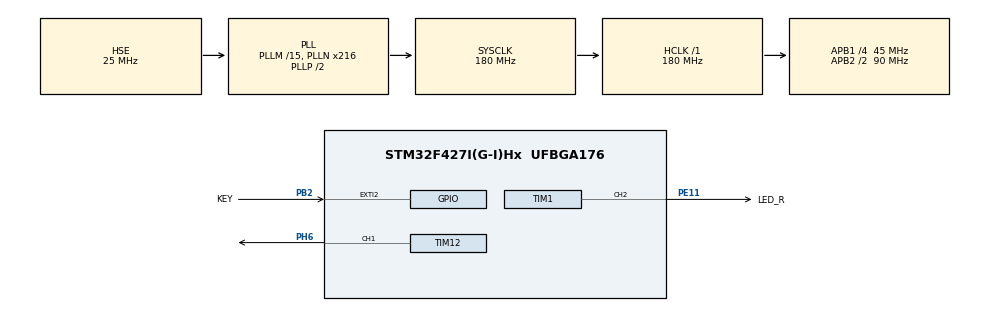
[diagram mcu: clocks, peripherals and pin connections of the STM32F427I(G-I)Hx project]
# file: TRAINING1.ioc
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IWDG.Prescaler=IWDG_PRESCALER_16
IWDG.Reload=3999
Mcu.Family=STM32F4
Mcu.Name=STM32F427I(G-I)Hx
Mcu.Package=UFBGA176
NVIC.EXTI2_IRQn=true\:0\:0\:true\:false\:true\:true\:true\:true
NVIC.PriorityGroup=NVIC_PRIORITYGROUP_4
PA13.Mode=Serial_Wire
PA13.Signal=SYS_JTMS-SWDIO
PA14.Mode=Serial_Wire
PA14.Signal=SYS_JTCK-SWCLK
PB2/BOOT1.GPIO_Label=KEY
PB2/BOOT1.GPIO_ModeDefaultEXTI=GPIO_MODE_IT_RISING
PB2/BOOT1.GPIO_PuPd=GPIO_PULLDOWN
PB2/BOOT1.Signal=GPXTI2
PE11.GPIO_Label=LED_R
PE11.Signal=S_TIM1_CH2
PH0/OSC_IN.Mode=HSE-External-Oscillator
PH0/OSC_IN.Signal=RCC_OSC_IN
PH1/OSC_OUT.Mode=HSE-External-Oscillator
PH1/OSC_OUT.Signal=RCC_OSC_OUT
PH6.Signal=S_TIM12_CH1
ProjectManager.HeapSize=0x200
ProjectManager.StackSize=0x400
ProjectManager.TargetToolchain=MDK-ARM V5.32
RCC.48MHZClocksFreq_Value=90000000
RCC.AHBFreq_Value=180000000
RCC.APB1CLKDivider=RCC_HCLK_DIV4
RCC.APB1Freq_Value=45000000
RCC.APB1TimFreq_Value=90000000
RCC.APB2CLKDivider=RCC_HCLK_DIV2
RCC.APB2Freq_Value=90000000
RCC.APB2TimFreq_Value=180000000
RCC.CortexFreq_Value=180000000
RCC.HCLKFreq_Value=180000000
RCC.HSE_VALUE=25000000
RCC.HSI_VALUE=16000000
RCC.LSE_VALUE=32768
RCC.PLLM=15
RCC.PLLN=216
RCC.PLLSourceVirtual=RCC_PLLSOURCE_HSE
RCC.SYSCLKFreq_VALUE=180000000
RCC.SYSCLKSource=RCC_SYSCLKSOURCE_PLLCLK
RCC.VCOOutputFreq_Value=360000000
SH.S_TIM12_CH1.0=TIM12_CH1,PWM Generation1 CH1
SH.S_TIM1_CH2.0=TIM1_CH2,PWM Generation2 CH2
TIM1.Channel-PWM\ Generation2\ CH2=TIM_CHANNEL_2
TIM1.OCMode_PWM-PWM\ Generation2\ CH2=TIM_OCMODE_PWM2
TIM1.Period=999
TIM1.Prescaler=179
TIM1.Pulse-PWM\ Generation2\ CH2=500
TIM12.Channel-PWM\ Generation1\ CH1=TIM_CHANNEL_1
TIM12.Period=999
TIM12.Prescaler=89
TIM12.Pulse-PWM\ Generation1\ CH1=500
VP_IWDG_VS_IWDG.Mode=IWDG_Activate
VP_TIM12_VS_ClockSourceINT.Mode=Internal
VP_TIM1_VS_ClockSourceINT.Mode=Internal
board=custom

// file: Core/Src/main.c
/* USER CODE BEGIN Header */
/**
  ******************************************************************************
  * @file           : main.c
  * @brief          : Main program body
  ******************************************************************************
  * @attention
  *
  * Copyright (c) 2026 STMicroelectronics.
  * All rights reserved.
  *
  * This software is licensed under terms that can be found in the LICENSE file
  * in the root directory of this software component.
  * If no LICENSE file comes with this software, it is provided AS-IS.
  *
  ******************************************************************************
  */
/* USER CODE END Header */
#include "main.h"
#include "iwdg.h"
#include "tim.h"
#include "gpio.h"

/* USER CODE BEGIN PV */
uint32_t ticks=0;
volatile uint8_t requested_mode = 0;
/* USER CODE END PV */

void SystemClock_Config(void);

int main(void)
{

  /* MCU Configuration--------------------------------------------------------*/

  /* Reset of all peripherals, Initializes the Flash interface and the Systick. */
  HAL_Init();

  /* Configure the system clock */
  SystemClock_Config();

  /* Initialize all configured peripherals */
  MX_GPIO_Init();
  MX_TIM1_Init();
  MX_TIM12_Init();
  MX_IWDG_Init();
  /* USER CODE BEGIN 2 */
  //HAL_TIM_Base_Start(&htim1);
  uint32_t ticks=0,last_tick1=0,last_tick2=0;
  int32_t pulse=0;
  uint8_t last_mode = 0;
  int8_t pulse_helper=1;
  const uint32_t interval1=10;
  const uint32_t interval2=500;
  HAL_TIM_PWM_Start(&htim1, TIM_CHANNEL_2);
  //HAL_TIM_PWM_Start(&htim12, TIM_CHANNEL_1);
  /* USER CODE END 2 */

  /* Infinite loop */
  /* USER CODE BEGIN WHILE */
  while (1)
  {
    if (HAL_GPIO_ReadPin(KEY_GPIO_Port, KEY_Pin) == GPIO_PIN_SET)
    {
      HAL_IWDG_Refresh(&hiwdg);
    }
    if (requested_mode != last_mode)
    {
      last_mode = requested_mode;
      if (requested_mode == 1)
      {
        pulse = 0;
        pulse_helper = 1;
        last_tick1 = ticks;
      }
      else if (requested_mode == 2)
      {
        pulse = 500;
        last_tick2 = ticks;
        __HAL_TIM_SET_COMPARE(&htim1, TIM_CHANNEL_2, 500);
      }
    }
    ticks=HAL_GetTick();
    if(requested_mode==0)
    {
      pulse=0;
      __HAL_TIM_SET_COMPARE(&htim1, TIM_CHANNEL_2, pulse);
    }
    else if (requested_mode==1)
    {
      if (ticks-last_tick1>=interval1)
      {
        pulse += (pulse_helper * 10);

        if (pulse >= 1000) {
          pulse = 1000;
          pulse_helper = -1;
        } else if (pulse <= 0) {
          pulse = 0;
          pulse_helper= 1;
        }
        last_tick1=ticks;
      }
      __HAL_TIM_SET_COMPARE(&htim1, TIM_CHANNEL_2, pulse);
    }
    else if (requested_mode==2)
    {
      if (ticks-last_tick2>=interval2)
      {
        if (pulse==500) pulse=0;
        else pulse=500;//PROBLEM!
        last_tick2 = ticks;
      }
      __HAL_TIM_SET_COMPARE(&htim1, TIM_CHANNEL_2, pulse);
    }
    //for (uint32_t pulse=0; pulse<1000;pulse++)
    //{
      //__HAL_TIM_SET_COMPARE(&htim1, TIM_CHANNEL_2, pulse);
      //HAL_Delay(2);
      //if (HAL_GPIO_ReadPin(KEY_GPIO_Port, KEY_Pin) == GPIO_PIN_SET) {
        //HAL_IWDG_Refresh(&hiwdg); // 按下按键时喂狗，重置计时器
      //}
    //}
    //for (uint32_t pulse=999; pulse>0;pulse--)
    //{
      //__HAL_TIM_SET_COMPARE(&htim1, TIM_CHANNEL_2, pulse);
      //HAL_Delay(2);
      //if (HAL_GPIO_ReadPin(KEY_GPIO_Port, KEY_Pin) == GPIO_PIN_SET) {
        //HAL_IWDG_Refresh(&hiwdg); // 按下按键时喂狗，重置计时器
      //}
    }
    //ticks = HAL_GetTick();
    //uint32_t counter=__HAL_TIM_GET_COUNTER(&htim1);
   // if (counter<=5000)
    //{
      //HAL_GPIO_WritePin(LED_R_GPIO_Port,LED_R_Pin,GPIO_PIN_RESET);
    //}
    //else
    //{
      //HAL_GPIO_WritePin(LED_R_GPIO_Port,LED_R_Pin,GPIO_PIN_SET);
    //}
    //HAL_GPIO_TogglePin(LED_R_GPIO_Port, LED_R_Pin);
    //HAL_Delay(100);
    /* USER CODE END WHILE */

    /* USER CODE BEGIN 3 */

  //}
  /* USER CODE END 3 */
}

void SystemClock_Config(void)
{
  RCC_OscInitTypeDef RCC_OscInitStruct = {0};
  RCC_ClkInitTypeDef RCC_ClkInitStruct = {0};

  /** Configure the main internal regulator output voltage
  */
  __HAL_RCC_PWR_CLK_ENABLE();
  __HAL_PWR_VOLTAGESCALING_CONFIG(PWR_REGULATOR_VOLTAGE_SCALE1);

  /** Initializes the RCC Oscillators according to the specified parameters
  * in the RCC_OscInitTypeDef structure.
  */
  RCC_OscInitStruct.OscillatorType = RCC_OSCILLATORTYPE_LSI|RCC_OSCILLATORTYPE_HSE;
  RCC_OscInitStruct.HSEState = RCC_HSE_ON;
  RCC_OscInitStruct.LSIState = RCC_LSI_ON;
  RCC_OscInitStruct.PLL.PLLState = RCC_PLL_ON;
  RCC_OscInitStruct.PLL.PLLSource = RCC_PLLSOURCE_HSE;
  RCC_OscInitStruct.PLL.PLLM = 15;
  RCC_OscInitStruct.PLL.PLLN = 216;
  RCC_OscInitStruct.PLL.PLLP = RCC_PLLP_DIV2;
  RCC_OscInitStruct.PLL.PLLQ = 4;
  if (HAL_RCC_OscConfig(&RCC_OscInitStruct) != HAL_OK)
  {
    Error_Handler();
  }

  /** Activate the Over-Drive mode
  */
  if (HAL_PWREx_EnableOverDrive() != HAL_OK)
  {
    Error_Handler();
  }

  /** Initializes the CPU, AHB and APB buses clocks
  */
  RCC_ClkInitStruct.ClockType = RCC_CLOCKTYPE_HCLK|RCC_CLOCKTYPE_SYSCLK
                              |RCC_CLOCKTYPE_PCLK1|RCC_CLOCKTYPE_PCLK2;
  RCC_ClkInitStruct.SYSCLKSource = RCC_SYSCLKSOURCE_PLLCLK;
  RCC_ClkInitStruct.AHBCLKDivider = RCC_SYSCLK_DIV1;
  RCC_ClkInitStruct.APB1CLKDivider = RCC_HCLK_DIV4;
  RCC_ClkInitStruct.APB2CLKDivider = RCC_HCLK_DIV2;

  if (HAL_RCC_ClockConfig(&RCC_ClkInitStruct, FLASH_LATENCY_5) != HAL_OK)
  {
    Error_Handler();
  }
}

/* USER CODE BEGIN 4 */
void HAL_GPIO_EXTI_Callback(uint16_t GPIO_Pin)
{
  if (GPIO_Pin == KEY_Pin) {
    static uint32_t last_key_tick = 0;
    static uint8_t has_last_key_tick = 0;
    uint32_t now = HAL_GetTick();

    if (!has_last_key_tick || (now - last_key_tick) >= 30U) {
      has_last_key_tick = 1;
      last_key_tick = now;
      requested_mode = (requested_mode + 1U) % 3U;
    }
  }
}
/* USER CODE END 4 */

void Error_Handler(void)
{
  __disable_irq();
  while (1)
  {
  }
}
